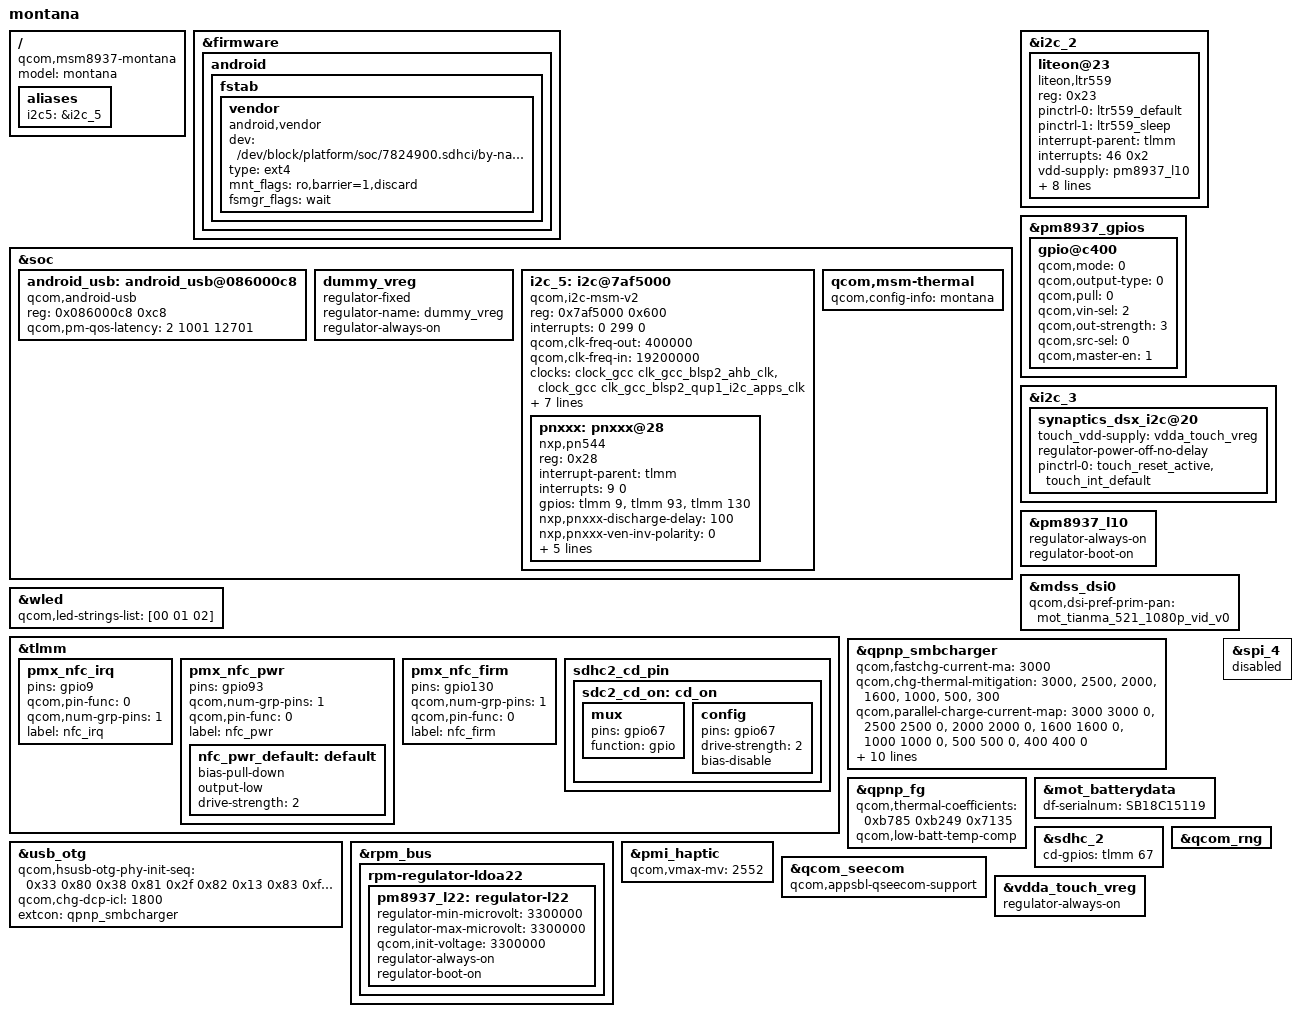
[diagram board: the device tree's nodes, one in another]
/* Copyright (c) 2016, Motorola Mobility Inc. All rights reserved.
 *
 * This program is free software; you can redistribute it and/or modify
 * it under the terms of the GNU General Public License version 2 and
 * only version 2 as published by the Free Software Foundation.
 *
 * This program is distributed in the hope that it will be useful,
 * but WITHOUT ANY WARRANTY; without even the implied warranty of
 * MERCHANTABILITY or FITNESS FOR A PARTICULAR PURPOSE.  See the
 * GNU General Public License for more details.
 */

#include "msm8937-moto-common-cedric-montana.dtsi"
#include "dsi-panel-mot-tianma-521-1080p-video.dtsi"
#include "dsi-panel-mot-inx-521-1080p-video.dtsi"
#include "msm8937-camera-sensor-mot-montana.dtsi"
#include "msm8937-montana-fps-overlay.dtsi"
#include "msm8937-montana-audio.dtsi"

 / {
	model = "montana";
	compatible = "qcom,msm8937-montana", "qcom,msm8937-moto",
			"qcom,msm8937";
	aliases {
		i2c5 = &i2c_5;
	};
};

&firmware {
	android {
		fstab {
			vendor {
				compatible = "android,vendor";
				dev = "/dev/block/platform/soc/7824900.sdhci/by-name/oem";
				type = "ext4";
				mnt_flags = "ro,barrier=1,discard";
				fsmgr_flags = "wait";
				status = "ok";
			};
		};
	};
};

&soc {
	android_usb: android_usb@086000c8 {
		compatible = "qcom,android-usb";
		reg = <0x086000c8 0xc8>;
		qcom,pm-qos-latency = <2 1001 12701>;
	};

	dummy_vreg: dummy_vreg {
		compatible = "regulator-fixed";
		status = "ok";
		regulator-name = "dummy_vreg";
		regulator-always-on;
	};

	i2c_5: i2c@7af5000 { /* BLSP2 QUP1 */
		status = "okay";
		compatible = "qcom,i2c-msm-v2";
		#address-cells = <1>;
		#size-cells = <0>;
		reg-names = "qup_phys_addr";
		reg = <0x7af5000 0x600>;
		interrupt-names = "qup_irq";
		interrupts = <0 299 0>;
		qcom,clk-freq-out = <400000>;
		qcom,clk-freq-in  = <19200000>;
		clock-names = "iface_clk", "core_clk";
		clocks = <&clock_gcc clk_gcc_blsp2_ahb_clk>,
			<&clock_gcc clk_gcc_blsp2_qup1_i2c_apps_clk>;

		pinctrl-names = "i2c_active", "i2c_sleep";
		pinctrl-0 = <&i2c_5_active>;
		pinctrl-1 = <&i2c_5_sleep>;
		qcom,noise-rjct-scl = <0>;
		qcom,noise-rjct-sda = <0>;
		qcom,master-id = <84>;
		dmas = <&dma_blsp2 4 64 0x20000020 0x20>,
			<&dma_blsp2 5 32 0x20000020 0x20>;
		dma-names = "tx", "rx";
	};

	qcom,msm-thermal {
		qcom,config-info = "montana";
	};
};

&i2c_2 {
	liteon@23 {
		compatible = "liteon,ltr559";
		reg = <0x23>;
		pinctrl-names = "default","sleep";
		pinctrl-0 = <&ltr559_default>;
		pinctrl-1 = <&ltr559_sleep>;
		interrupt-parent = <&tlmm>;
		interrupts = <46 0x2>;
		vdd-supply = <&pm8937_l10>;
		vio-supply = <&pm8937_l6>;
		ltr,irq-gpio = <&tlmm 46 0x2>;
		ltr,ps-faroffset = <30>;
		ltr,ps-nearoffset = <40>;
		ltr,ps-threshold = <800>;
		ltr,ps-hysteresis-threshold = <300>;
		ltr,als-polling-time = <200>;
		ltr,prox-sensor-name = "Rear Proximity sensor";
	};
};

&pm8937_gpios {
	gpio@c400 {
		qcom,mode = <0>;
		qcom,output-type = <0>;
		qcom,pull = <0>;
		qcom,vin-sel = <2>;
		qcom,out-strength = <3>;
		qcom,src-sel = <0>;
		qcom,master-en = <1>;
		status = "okay";
	};
};

&i2c_5 { /* BLSP2 QUP1 (NFC) */
	pnxxx: pnxxx@28 {
	    compatible = "nxp,pn544";
	    reg = <0x28>;
	    interrupt-parent = <&tlmm>;
	    interrupts = <9 0>;
	    gpios = <&tlmm 9 0>, /* IRQ */
	    <&tlmm 93 0>, /* VEN */
	    <&tlmm 130 0>; /* Firmware */

	    nxp,pnxxx-discharge-delay = <100>;
	    nxp,pnxxx-ven-inv-polarity = <0>;

	    pinctrl-names = "default";
	    pinctrl-0=<&nfc_irq_default &nfc_pwr_default &nfc_firm_default>;

	    qcom,clk-gpio = <&pm8937_gpios 5 0x00>;
	    qcom,clk-src = "BBCLK2";
	    clocks = <&clock_gcc clk_bb_clk2_pin>;
	    clock-names = "ref_clk";
	};
};

&i2c_3 {
	synaptics_dsx_i2c@20 {
		touch_vdd-supply = <&vdda_touch_vreg>;
		regulator-power-off-no-delay;
		pinctrl-0 = <&touch_reset_active &touch_int_default>;
	};
};

&pm8937_l10 {
	regulator-always-on;
	regulator-boot-on;
};

&mdss_dsi0 {
	qcom,dsi-pref-prim-pan = <&mot_tianma_521_1080p_vid_v0>;
};

&wled {
	qcom,led-strings-list = [00 01 02];
};

&tlmm {
	/delete-node/ spi7;

	pmx_nfc_irq {
		pins = "gpio9";
		qcom,pin-func = <0>;
		qcom,num-grp-pins = <1>;
		label = "nfc_irq";
	};

	pmx_nfc_pwr {
		pins = "gpio93";
		qcom,num-grp-pins = <1>;
		qcom,pin-func = <0>;
		label = "nfc_pwr";

		nfc_pwr_default: default {
			bias-pull-down;
			output-low;
			drive-strength = <2>;
		};
	};

	pmx_nfc_firm {
		pins = "gpio130";
		qcom,num-grp-pins = <1>;
		qcom,pin-func = <0>;
		label = "nfc_firm";
	};

	sdhc2_cd_pin {
        sdc2_cd_on: cd_on {
			mux {
                pins = "gpio67";
                function = "gpio";
            };

            config {
                pins = "gpio67";
                drive-strength = <2>;
        		/delete-property/ bias-pull-up;
        		bias-disable;
            };
        };
    };
};

&qpnp_smbcharger {
	qcom,fastchg-current-ma = <3000>;
	qcom,chg-thermal-mitigation = <3000>, <2500>, <2000>, <1600>,
		<1000>, <500>, <300>;
	qcom,parallel-charge-current-map = <3000 3000 0>,
					   <2500 2500 0>,
					   <2000 2000 0>,
					   <1600 1600 0>,
					   <1000 1000 0>,
					   <500 500 0>,
					   <400 400 0>;
	qcom,stepchg-voltage-mv = <4200>;
	qcom,stepchg-current-ma = <2000>;
	qcom,stepchg-taper-ma = <1800>;
	qcom,temp-warm-current-ma = <1500>;
	qcom,temp-cool-current-ma = <600>;
	qcom,temp-slightly-cool-current-ma = <600>;
	qcom,slightly-cool-temp-c = <15>;
	qcom,enable-charging-limit;
	qcom,upper-limit-capacity = <70>;
	qcom,lower-limit-capacity = <60>;
};

&qpnp_fg {
	qcom,thermal-coefficients =  /bits/ 16 <0xb785 0xb249 0x7135>;
	qcom,low-batt-temp-comp;
};

&mot_batterydata {
	df-serialnum = "SB18C15119";
	#include "batterydata-hg30-atl.dtsi"
	#include "batterydata-hg30-swd.dtsi"
};

&usb_otg {
	qcom,hsusb-otg-phy-init-seq =
		<0x33 0x80 0x38 0x81 0x2f 0x82 0x13 0x83 0xffffffff>;
	qcom,chg-dcp-icl = <1800>;
	extcon = <&qpnp_smbcharger>;
};

&rpm_bus {
	rpm-regulator-ldoa22 {
		status = "okay";
		pm8937_l22: regulator-l22 {
			regulator-min-microvolt = <3300000>;
			regulator-max-microvolt = <3300000>;
			qcom,init-voltage = <3300000>;
			regulator-always-on;
			regulator-boot-on;
			status = "okay";
		};
	};
};

&sdhc_2 {
	cd-gpios = <&tlmm 67 0x0>;
};

&pmi_haptic {
	qcom,vmax-mv = <2552>;
};

&spi_4 { /* BLSP1 QUP4 */
    status = "disabled";
    /delete-node/ stml0xx@0;
};

&qcom_seecom {
	/delete-property/ qcom,commonlib64-loaded-by-uefi;
	qcom,appsbl-qseecom-support;
};

&qcom_rng {
	status = "okay";
};

&vdda_touch_vreg {
	regulator-always-on;
};
